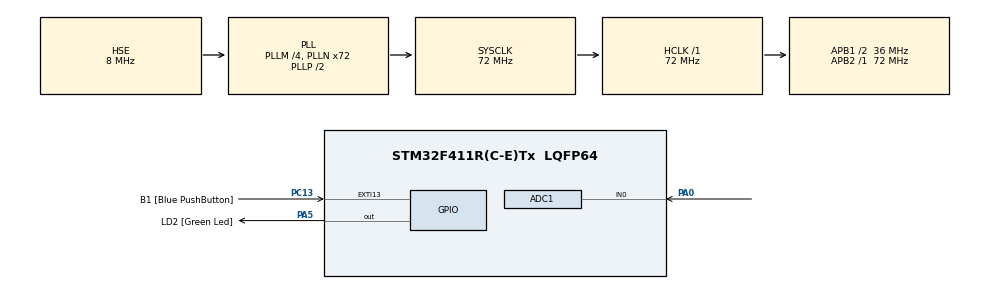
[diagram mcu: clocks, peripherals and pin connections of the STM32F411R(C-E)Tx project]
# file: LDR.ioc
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Mcu.Family=STM32F4
RCC.PLLSourceVirtual=RCC_PLLSOURCE_HSE
RCC.CortexFreq_Value=72000000
ADC1.Rank-0\#ChannelRegularConversion=1
ADC1.ContinuousConvMode=ENABLE
PC13-ANTI_TAMP.GPIO_Label=B1 [Blue PushButton]
PA14.GPIO_Label=TCK
PH1\ -\ OSC_OUT.Mode=HSE-External-Oscillator
RCC.APB1CLKDivider=RCC_HCLK_DIV2
PC14-OSC32_IN.Signal=RCC_OSC32_IN
RCC.SYSCLKSource=RCC_SYSCLKSOURCE_PLLCLK
ProjectManager.StackSize=0x400
PA0-WKUP.Signal=ADCx_IN0
PA13.Signal=SYS_JTMS-SWDIO
NVIC.ADC_IRQn=true\:0\:0\:false\:false\:true\:true\:true
PH0\ -\ OSC_IN.Mode=HSE-External-Oscillator
PH0\ -\ OSC_IN.Signal=RCC_OSC_IN
ProjectManager.TargetToolchain=STM32CubeIDE
RCC.HCLKFreq_Value=72000000
ADC1.Resolution=ADC_RESOLUTION_8B
RCC.APB2TimFreq_Value=72000000
RCC.LSE_VALUE=32768
PC15-OSC32_OUT.Signal=RCC_OSC32_OUT
RCC.AHBFreq_Value=72000000
PA5.Signal=GPIO_Output
ADC1.Channel-0\#ChannelRegularConversion=ADC_CHANNEL_0
RCC.HSE_VALUE=8000000
PH1\ -\ OSC_OUT.Signal=RCC_OSC_OUT
board=NUCLEO-F411RE
PC13-ANTI_TAMP.Signal=GPXTI13
RCC.VCOOutputFreq_Value=144000000
RCC.APB2Freq_Value=72000000
SH.ADCx_IN0.0=ADC1_IN0,IN0
ADC1.NbrOfConversion=1
Mcu.Name=STM32F411R(C-E)Tx
ADC1.SamplingTime-0\#ChannelRegularConversion=ADC_SAMPLETIME_480CYCLES
PA2.Signal=USART2_TX
PA13.GPIO_Label=TMS
RCC.FLatency-AdvancedSettings=FLASH_LATENCY_2
RCC.48MHZClocksFreq_Value=36000000
PB3.Signal=SYS_JTDO-SWO
RCC.SYSCLKFreq_VALUE=72000000
Mcu.Package=LQFP64
ADC1.master=1
PA5.GPIO_Label=LD2 [Green Led]
PC13-ANTI_TAMP.GPIO_ModeDefaultEXTI=GPIO_MODE_IT_FALLING
PA2.GPIO_Label=USART_TX
PA14.Signal=SYS_JTCK-SWCLK
ProjectManager.HeapSize=0x200
RCC.HSI_VALUE=16000000
NVIC.PriorityGroup=NVIC_PRIORITYGROUP_0
ADC1.NbrOfConversionFlag=1
RCC.PLLM=4
RCC.PLLN=72
RCC.APB1TimFreq_Value=72000000
RCC.APB1Freq_Value=36000000
PA3.GPIO_Label=USART_RX
PA3.Signal=USART2_RX
PB3.GPIO_Label=SWO

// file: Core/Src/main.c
/* USER CODE BEGIN Header */
/**
  ******************************************************************************
  * @file           : main.c
  * @brief          : Main program body
  ******************************************************************************
  * @attention
  *
  * <h2><center>&copy; Copyright (c) 2021 STMicroelectronics.
  * All rights reserved.</center></h2>
  *
  * This software component is licensed by ST under BSD 3-Clause license,
  * the "License"; You may not use this file except in compliance with the
  * License. You may obtain a copy of the License at:
  *                        opensource.org/licenses/BSD-3-Clause
  *
  ******************************************************************************
  */
/* USER CODE END Header */
#include "main.h"

ADC_HandleTypeDef hadc1;

void SystemClock_Config(void);
static void MX_GPIO_Init(void);
static void MX_ADC1_Init(void);

/* USER CODE BEGIN 0 */
int x;
int status = 0;

void HAL_ADC_ConvCpltCallback(ADC_HandleTypeDef *hadc)
{
	if (hadc == &hadc1)
	{
		x = HAL_ADC_GetValue(&hadc1);

		if (x == 255)
		{
			x = 50;
			HAL_ADC_Stop_IT(&hadc1);
			status = 1;
		}
	}
}
/* USER CODE END 0 */

int main(void)
{

  /* MCU Configuration--------------------------------------------------------*/

  /* Reset of all peripherals, Initializes the Flash interface and the Systick. */
  HAL_Init();

  /* Configure the system clock */
  SystemClock_Config();

  /* Initialize all configured peripherals */
  MX_GPIO_Init();
  MX_ADC1_Init();
  /* USER CODE BEGIN 2 */

  HAL_ADC_Start_IT(&hadc1);

  /* USER CODE END 2 */

  /* Infinite loop */
  while (1)
  {
	  HAL_Delay(5000);
	  if (status == 1)
	  {
		  HAL_ADC_Start_IT(&hadc1);
		  status = 0;
	  }
  }
}

void SystemClock_Config(void)
{
  RCC_OscInitTypeDef RCC_OscInitStruct = {0};
  RCC_ClkInitTypeDef RCC_ClkInitStruct = {0};

  /** Configure the main internal regulator output voltage
  */
  __HAL_RCC_PWR_CLK_ENABLE();
  __HAL_PWR_VOLTAGESCALING_CONFIG(PWR_REGULATOR_VOLTAGE_SCALE1);
  /** Initializes the RCC Oscillators according to the specified parameters
  * in the RCC_OscInitTypeDef structure.
  */
  RCC_OscInitStruct.OscillatorType = RCC_OSCILLATORTYPE_HSE;
  RCC_OscInitStruct.HSEState = RCC_HSE_ON;
  RCC_OscInitStruct.PLL.PLLState = RCC_PLL_ON;
  RCC_OscInitStruct.PLL.PLLSource = RCC_PLLSOURCE_HSE;
  RCC_OscInitStruct.PLL.PLLM = 4;
  RCC_OscInitStruct.PLL.PLLN = 72;
  RCC_OscInitStruct.PLL.PLLP = RCC_PLLP_DIV2;
  RCC_OscInitStruct.PLL.PLLQ = 4;
  if (HAL_RCC_OscConfig(&RCC_OscInitStruct) != HAL_OK)
  {
    Error_Handler();
  }
  /** Initializes the CPU, AHB and APB buses clocks
  */
  RCC_ClkInitStruct.ClockType = RCC_CLOCKTYPE_HCLK|RCC_CLOCKTYPE_SYSCLK
                              |RCC_CLOCKTYPE_PCLK1|RCC_CLOCKTYPE_PCLK2;
  RCC_ClkInitStruct.SYSCLKSource = RCC_SYSCLKSOURCE_PLLCLK;
  RCC_ClkInitStruct.AHBCLKDivider = RCC_SYSCLK_DIV1;
  RCC_ClkInitStruct.APB1CLKDivider = RCC_HCLK_DIV2;
  RCC_ClkInitStruct.APB2CLKDivider = RCC_HCLK_DIV1;

  if (HAL_RCC_ClockConfig(&RCC_ClkInitStruct, FLASH_LATENCY_2) != HAL_OK)
  {
    Error_Handler();
  }
}

static void MX_ADC1_Init(void)
{

  ADC_ChannelConfTypeDef sConfig = {0};

  /** Configure the global features of the ADC (Clock, Resolution, Data Alignment and number of conversion)
  */
  hadc1.Instance = ADC1;
  hadc1.Init.ClockPrescaler = ADC_CLOCK_SYNC_PCLK_DIV2;
  hadc1.Init.Resolution = ADC_RESOLUTION_8B;
  hadc1.Init.ScanConvMode = DISABLE;
  hadc1.Init.ContinuousConvMode = ENABLE;
  hadc1.Init.DiscontinuousConvMode = DISABLE;
  hadc1.Init.ExternalTrigConvEdge = ADC_EXTERNALTRIGCONVEDGE_NONE;
  hadc1.Init.ExternalTrigConv = ADC_SOFTWARE_START;
  hadc1.Init.DataAlign = ADC_DATAALIGN_RIGHT;
  hadc1.Init.NbrOfConversion = 1;
  hadc1.Init.DMAContinuousRequests = DISABLE;
  hadc1.Init.EOCSelection = ADC_EOC_SINGLE_CONV;
  if (HAL_ADC_Init(&hadc1) != HAL_OK)
  {
    Error_Handler();
  }
  /** Configure for the selected ADC regular channel its corresponding rank in the sequencer and its sample time.
  */
  sConfig.Channel = ADC_CHANNEL_0;
  sConfig.Rank = 1;
  sConfig.SamplingTime = ADC_SAMPLETIME_480CYCLES;
  if (HAL_ADC_ConfigChannel(&hadc1, &sConfig) != HAL_OK)
  {
    Error_Handler();
  }

}

static void MX_GPIO_Init(void)
{
  GPIO_InitTypeDef GPIO_InitStruct = {0};

  /* GPIO Ports Clock Enable */
  __HAL_RCC_GPIOC_CLK_ENABLE();
  __HAL_RCC_GPIOH_CLK_ENABLE();
  __HAL_RCC_GPIOA_CLK_ENABLE();
  __HAL_RCC_GPIOB_CLK_ENABLE();

  /*Configure GPIO pin Output Level */
  HAL_GPIO_WritePin(LD2_GPIO_Port, LD2_Pin, GPIO_PIN_RESET);

  /*Configure GPIO pin : B1_Pin */
  GPIO_InitStruct.Pin = B1_Pin;
  GPIO_InitStruct.Mode = GPIO_MODE_IT_FALLING;
  GPIO_InitStruct.Pull = GPIO_NOPULL;
  HAL_GPIO_Init(B1_GPIO_Port, &GPIO_InitStruct);

  /*Configure GPIO pins : USART_TX_Pin USART_RX_Pin */
  GPIO_InitStruct.Pin = USART_TX_Pin|USART_RX_Pin;
  GPIO_InitStruct.Mode = GPIO_MODE_AF_PP;
  GPIO_InitStruct.Pull = GPIO_NOPULL;
  GPIO_InitStruct.Speed = GPIO_SPEED_FREQ_VERY_HIGH;
  GPIO_InitStruct.Alternate = GPIO_AF7_USART2;
  HAL_GPIO_Init(GPIOA, &GPIO_InitStruct);

  /*Configure GPIO pin : LD2_Pin */
  GPIO_InitStruct.Pin = LD2_Pin;
  GPIO_InitStruct.Mode = GPIO_MODE_OUTPUT_PP;
  GPIO_InitStruct.Pull = GPIO_NOPULL;
  GPIO_InitStruct.Speed = GPIO_SPEED_FREQ_LOW;
  HAL_GPIO_Init(LD2_GPIO_Port, &GPIO_InitStruct);

}

void Error_Handler(void)
{
  __disable_irq();
  while (1)
  {
  }
}

/************************ (C) COPYRIGHT STMicroelectronics *****END OF FILE****/
